# M051DE_v1 register map
File version: 1.0
Registers are 32-bit, read-write, reset 0x0 unless marked. A register's access mark holds for its fields unless they carry their own. Offsets are from the block's base; [hi:lo] are bit positions; {n}, {i} and the like mark numbered series; 'fields as' and 'values as' point back to an identical list.

## ADC — ADC Register Map
Base 0x400E0000
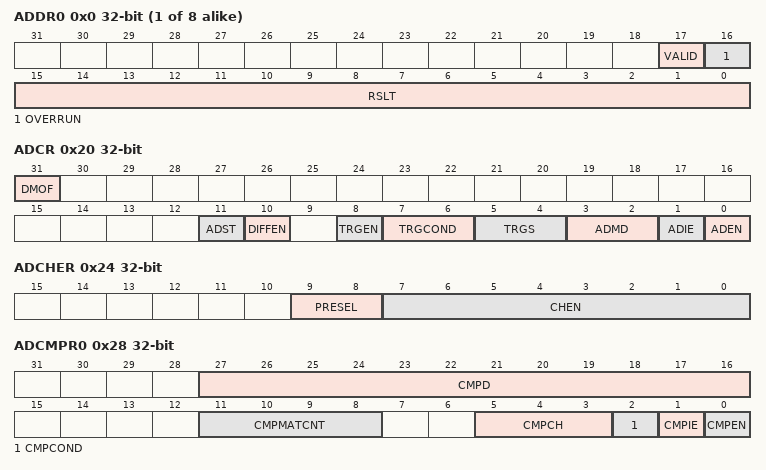
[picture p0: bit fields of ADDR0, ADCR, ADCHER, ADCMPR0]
{0x0+4i} ADDR{i} ro (i=0..7) — ADC Data Register {i}
  [17] VALID — Valid Flag. This bit will be set to 1 when the conversion of the corresponding channel is completed. This bit will be cleared to 0 by hardware after ADDR register is read. This is a read only bit. Note: When ADC is converting, if user wants to monitor the VALID flag of a specified channel, user should poll the VALID bit of ADSR register instead of polling this bit (M05xxBN only).
    0=Data in RSLT bits is not valid; 1=Data in RSLT bits is valid
  [16] OVERRUN — Overrun Flag (Read Only). If converted data in RSLT has not been read before new conversion result is loaded to this register, OVERRUN is set to 1. It is cleared by hardware after ADDR register is read.
    0=Data in RSLT is not overwrote; 1=Data in RSLT is overwrote
  [15:0] RSLT — A/D Conversion Result. This field contains conversion result of ADC.
0x20 ADCR — ADC Control Register
  [31] DMOF — Differential Input Mode Output Format. Note: Burst mode and ADC compare function cannot suppert 2's complement output format, this DMOF bit must be cleared to 0 (M05xxBN only).
    0=A/D Conversion result will be filled in RSLT at ADDRx registers with unsigned format (straight binary format); 1=A/D Conversion result will be filled in RSLT at ADDRx registers with 2's complement format
  [11] ADST — A/D Conversion Start. ADST bit can be set to 1 from two sources: software or external pin STADC. ADST will be cleared to 0 by hardware automatically at the ends of Single mode and Single-cycle Scan mode. In Continuous Scan mode and Burst mode, A/D conversion is continuously performed until software writes 0 to this bit or chip is reset. Note: After the ADST bit is cleared to 0, user must wait at least one ADC peripheral clock cycle before setting the ADST bit to 1 again (M05xxBN only).
    0=Conversion stops and A/D converter enters idle state; 1=Conversion starts
  [10] DIFFEN — Differential Input Mode Control
    0=Single-end analog input mode; 1=Differential analog input mode
  [8] TRGEN — External Trigger Enable Control. Enable or disable triggering of A/D conversion by external STADC pin. If external trigger is enabled, the ADST bit can be set to 1 by the selected hardware trigger source. Note: The ADC external trigger function is only supported in Single-cycle Scan mode.
    0=External trigger Disabled; 1=External trigger Enabled
  [7:6] TRGCOND — External Trigger Condition. These two bits decide external pin STADC trigger event is level or edge. The signal must be kept at stable state at least 8 PCLKs for level trigger and at least 4 PCLKs for edge trigger.
    0=Low level; 1=High level; 2=Falling edge; 3=Rising edge
  [5:4] TRGS — Hardware Trigger Source. Software should clear TRGEN bit and ADST bit to 0 before changing TRGS. Note: ADC hardware trigger source does not support PWM trigger (M05xxBN only).
    0=A/D conversion is started by external STADC pin; 3=A/D conversion is started by PWM trigger
  [3:2] ADMD — A/D Converter Operation Mode Control. Note1: When changing the operation mode, software should clear ADST bit firstly. Note2: In Burst mode, the A/D result data always at Data Register 0.
    0=Single conversion; 1=Burst conversion; 2=Single-cycle Scan; 3=Continuous Scan
  [1] ADIE — A/D Interrupt Enable Control. A/D conversion end interrupt request is generated if ADIE bit is set to 1.
    0=A/D interrupt function Disabled; 1=A/D interrupt function Enabled
  [0] ADEN — A/D Converter Enable. Note: Before starting A/D conversion function, this bit should be set to 1. Clear it to 0 to disable A/D converter analog circuit to save power consumption.
    0=A/D converter Disabled; 1=A/D converter Enabled
0x24 ADCHER — ADC Channel Enable Register
  [9:8] PRESEL — Analog Input Channel 7 Source Selection. Note: When the band-gap voltage is selected as the analog input source of ADC channel 7, ADC peripheral clock rate needs to be limited to lower than 300 kHz.
    0=External analog input; 1=Internal band-gap voltage; 2=Internal temperature sensor
  [7:0] CHEN — Analog Input Channel Enable Control. Set CHEN[7:0] to enable the corresponding analog input channel 7 ~ 0. If DIFFEN bit is set to 1, only the even number channel needs to be enabled.
    0=Channel Disabled; 1=Channel Enabled
0x28 ADCMPR0 — ADC Compare Register 0
  [27:16] CMPD — Comparison Data. The 12-bit data is used to compare with conversion result of specified channel. Note: When DIFFEN bit is set to 1, ADC comparator compares CMPD with conversion result with unsigned format (M05xxBN only). CMPD should be filled in unsigned format (straight binary format).
  [11:8] CMPMATCNT — Compare Match Count. When the specified A/D channel analog conversion result matches the compare condition defined by CMPCOND[2], the internal match counter will increase 1. When the internal counter reaches the value to (CMPMATCNT +1), the CMPFx bit will be set.
  [5:3] CMPCH — Compare Channel Selection
    {v}=Channel {v} conversion result is selected to be compared (v=0..7)
  [2] CMPCOND — Compare Condition. Note: When the internal counter reaches to (CMPMATCNT +1), the CMPFx bit will be set.
    0=Set the compare condition as that when a 12-bit A/D conversion result is less than the 12-bit CMPD (ADCMPRx[27:16]), the internal match counter will increase one; 1=Set the compare condition as that when a 12-bit A/D conversion result is greater than or equal to the 12-bit CMPD (ADCMPRx[27:16]), the internal match counter will increase one
  [1] CMPIE — Compare Interrupt Enable Control. If the compare function is enabled and the compare condition matches the setting of CMPCOND and CMPMATCNT, CMPFx bit will be asserted, in the meanwhile, if CMPIE is set to 1, a compare interrupt request is generated.
    0=Compare function interrupt Disabled; 1=Compare function interrupt Enabled
  [0] CMPEN — Compare Enable Control. Set this bit to 1 to enable ADC controller to compare CMPD[11:0] with specified channel conversion result when converted data is loaded into ADDR register.
    0=Compare function Disabled; 1=Compare function Enabled
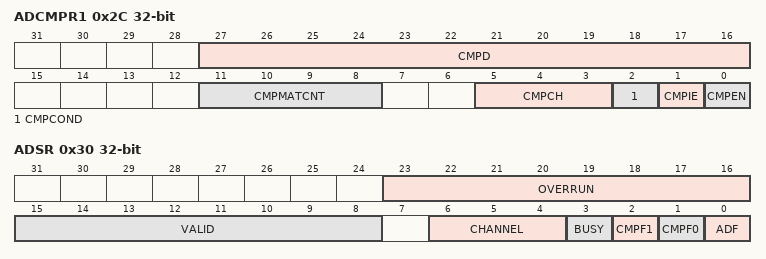
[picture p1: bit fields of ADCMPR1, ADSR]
0x2C ADCMPR1 — ADC Compare Register 1
  fields as ADCMPR0
0x30 ADSR — ADC Status Register
  [23:16] OVERRUN ro — Overrun Flag (Read Only). It is a mirror of OVERRUN bit in ADDRx register. When ADC is in Burst mode and the FIFO is overrun, all bits of OVERRUN[7:0] will be set to 1.
  [15:8] VALID ro — Data Valid Flag (Read Only). It is a mirror of VALID bit in ADDRx register. When ADC is in Burst mode and any conversion result is valid, all bits of VALID[7:0] will be set to 1.
  [6:4] CHANNEL — Current Conversion Channel. It is read only.
  [3] BUSY — BUSY/IDLE. This bit is a mirror of ADST bit in ADCR register. It is read only.
    0=A/D converter is in idle state; 1=A/D converter is busy at conversion
  [2] CMPF1 — Compare Flag 1. When the A/D conversion result of the selected channel meets setting condition in ADCMPR1 then this bit is set to 1; it is cleared by writing 1 to self.
    0=Conversion result in ADDR does not meet ADCMPR1 setting; 1=Conversion result in ADDR meets ADCMPR1 setting
  [1] CMPF0 — Compare Flag 0. When the A/D conversion result of the selected channel meets setting condition in ADCMPR0 then this bit is set to 1. This bit is cleared by writing 1 to it.
    0=Conversion result in ADDR does not meet ADCMPR0 setting; 1=Conversion result in ADDR meets ADCMPR0 setting
  [0] ADF — A/D Conversion End Flag. A status flag that indicates the end of A/D conversion. Software can write 1 to clear this bit. ADF is set to 1 at the following three conditions: When A/D conversion ends in Single mode. When A/D conversion ends on all specified channels in Single-cycle Scan mode and Continuous Scan mode. When more than 4 samples in FIFO in Burst mode.
0x44 ADTDCR — ADC Trigger Delay Control Register (M05xxDN/DE Only)
  [7:0] PTDT — PWM Trigger Delay Time. Set this field will delay ADC start conversion time after PWM trigger. PWM trigger delay time is (4 * PTDT) * system clock
